AUTOSAR XML (schema 00048)
package /SecurityArchitecture/ComponentTypes
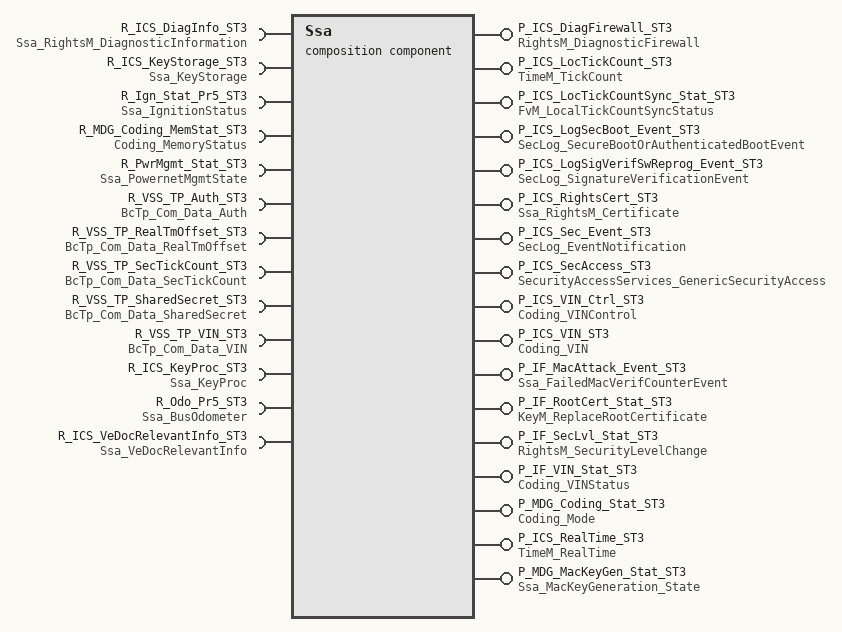
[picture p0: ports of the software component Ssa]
  composition sw component type Ssa: data-type-mapping=SSATypeMappingSet
    15 x provide port:
      P_ICS_DiagFirewall_ST3: provided-interface=RightsM_DiagnosticFirewall
        provided-com-specs:
          operation=GetDiagnosticUserRole, queue-length=1
          operation=IsEnhancedAccessRightGranted, queue-length=1
      P_ICS_LocTickCount_ST3: server-com-spec{operation=Get, queue-length=1}, provided-interface=TimeM_TickCount
      P_ICS_LocTickCountSync_Stat_ST3: server-com-spec{operation=Get, queue-length=1}, provided-interface=FvM_LocalTickCountSyncStatus
      P_ICS_LogSecBoot_Event_ST3: server-com-spec{operation=SecureBootOrAuthenticatedBoot, queue-length=1}, provided-interface=SecLog_SecureBootOrAuthenticatedBootEvent
      P_ICS_LogSigVerifSwReprog_Event_ST3: server-com-spec{operation=SignatureVerification, queue-length=1}, provided-interface=SecLog_SignatureVerificationEvent
      P_ICS_RightsCert_ST3: server-com-spec{operation=GetDiagAuthCertSerialNumber_SecurityAccess, queue-length=1}, provided-interface=Ssa_RightsM_Certificate
      P_ICS_Sec_Event_ST3: nonqueued-sender-com-spec{data-element=Data, init-value=constant-reference=Ssa_Init_Zero_7Byte}, provided-interface=SecLog_EventNotification
      P_ICS_SecAccess_ST3: provided-com-specs=[{operation=CompareKey, queue-length=1}, {operation=GetSeed, queue-length=1}], provided-interface=SecurityAccessServices_GenericSecurityAccess
      P_ICS_VIN_Ctrl_ST3: provided-interface=Coding_VINControl
        provided-com-specs:
          operation=GetStoreState, queue-length=1
          operation=Lock, queue-length=1
          operation=Set, queue-length=1
      P_ICS_VIN_ST3: server-com-spec{operation=Get, queue-length=1}, provided-interface=Coding_VIN
      P_IF_MacAttack_Event_ST3: queued-sender-com-spec=data-element=Event, provided-interface=Ssa_FailedMacVerifCounterEvent
      P_IF_RootCert_Stat_ST3: nonqueued-sender-com-spec{data-element=isProductive, init-value=constant-reference=Ssa_Init_boolean_False}, provided-interface=KeyM_ReplaceRootCertificate  # Notifies application about the change of the root certificate to a productive one.
      P_IF_SecLvl_Stat_ST3: nonqueued-sender-com-spec{data-element=currentLevel, init-value=constant-reference=Ssa_Init_Zero_uint8}, provided-interface=RightsM_SecurityLevelChange
      P_IF_VIN_Stat_ST3: nonqueued-sender-com-spec{data-element=status, init-value=constant-reference=Ssa_Init_VINStatus_VIN_STATUS_VIN_CORRECT_RECEIVED}, provided-interface=Coding_VINStatus  # Notifies application about the VIN status.
      P_MDG_Coding_Stat_ST3: mode-switch-sender-com-spec{enhanced-mode-api=false, mode-group=CodingStatus, queue-length=1}, provided-interface=Coding_Mode  # Notifies application about an ongoing, successful or failed coding attempt.
    10 x require port:
      R_ICS_DiagInfo_ST3: client-com-spec=Get, required-interface=Ssa_RightsM_DiagnosticInformation
      R_ICS_KeyStorage_ST3: client-com-spec=StorePermanently, required-interface=Ssa_KeyStorage  # Requests for storing the key material or certificates permanently i.e. for making them persistent.
      R_Ign_Stat_Pr5_ST3: nonqueued-receiver-com-spec{data-element=Ign_Stat_Pr5_ST3, end-to-end-transformation-com-spec-props=disable-end-to-end-check=true, filter=data-filter-type=ALWAYS, init-value=constant-reference=Ssa_Init_IgnitionStatus}, required-interface=Ssa_IgnitionStatus
      R_MDG_Coding_MemStat_ST3: mode-switch-receiver-com-spec{enhanced-mode-api=false, mode-group=MemoryStatus, supports-asynchronous-mode-switch=false}, required-interface=Coding_MemoryStatus
      R_PwrMgmt_Stat_ST3: nonqueued-receiver-com-spec{data-element=PN14_DDP_Sw_Stat_ST3, filter=data-filter-type=ALWAYS, init-value=constant-reference=Ssa_Init_PowernetMgmtState}, required-interface=Ssa_PowernetMgmtState
      R_VSS_TP_Auth_ST3: nonqueued-receiver-com-spec{data-element=VSS_TP_Auth_ST3, filter=data-filter-type=ALWAYS, init-value=constant-reference=Ssa_Init_ComSignal_8Byte}, required-interface=BcTp_Com_Data_Auth  # Configuration Variant(s): Not in VSM.
      R_VSS_TP_RealTmOffset_ST3: nonqueued-receiver-com-spec{data-element=VSS_TP_RealTmOffset_ST3, filter=data-filter-type=ALWAYS, init-value=constant-reference=Ssa_Init_ComSignal_8Byte}, required-interface=BcTp_Com_Data_RealTmOffset  # Configuration Variant(s): Not in VSM.
      R_VSS_TP_SecTickCount_ST3: nonqueued-receiver-com-spec{data-element=VSS_TP_SecTickCount_ST3, alive-timeout=1, filter=data-filter-type=ALWAYS, init-value=constant-reference=Ssa_Init_ComSignal_8Byte}, required-interface=BcTp_Com_Data_SecTickCount  # Configuration Variant(s): Not in VSM.
      R_VSS_TP_SharedSecret_ST3: nonqueued-receiver-com-spec{data-element=VSS_TP_SharedSecret_ST3, filter=data-filter-type=ALWAYS, init-value=constant-reference=Ssa_Init_ComSignal_8Byte}, required-interface=BcTp_Com_Data_SharedSecret  # Configuration Variant(s): Not in VSM.
      R_VSS_TP_VIN_ST3: nonqueued-receiver-com-spec{data-element=VSS_TP_VIN_ST3, alive-timeout=5, filter=data-filter-type=ALWAYS, init-value=constant-reference=Ssa_Init_ComSignal_8Byte}, required-interface=BcTp_Com_Data_VIN  # Configuration Variant(s): Not in VSM.
    provide port P_ICS_RealTime_ST3: provided-com-specs=[{operation=Compare, queue-length=1}, {operation=Get, queue-length=1}, {operation=Set, queue-length=1}], provided-interface=TimeM_RealTime
    require port R_ICS_KeyProc_ST3: required-com-specs=[GenerateKeyPair, PrepareKeyExchange], required-interface=Ssa_KeyProc  # Requests for preparing the key exchange operation, e.g. for generating the private key.
    require port R_Odo_Pr5_ST3: nonqueued-receiver-com-spec{data-element=DI_Odo_Pr5_ST3, end-to-end-transformation-com-spec-props=disable-end-to-end-check=true, filter=data-filter-type=ALWAYS, init-value=constant-reference=Ssa_Init_BusOdometerRecord}, required-interface=Ssa_BusOdometer
    provide port P_MDG_MacKeyGen_Stat_ST3: mode-switch-sender-com-spec{enhanced-mode-api=false, mode-group=State, queue-length=1}, provided-interface=Ssa_MacKeyGeneration_State  # Notifies application about an ongoing MAC key generation.
    require port R_ICS_VeDocRelevantInfo_ST3: client-com-spec=GetData, required-interface=Ssa_VeDocRelevantInfo  # Requests for the VeDoc relevant information, e.g., to be used as common name in the Trust Model CSR.
    10 x component:
      Ssa_BcTp: type=Ssa_BcTp
      Ssa_Cdd: type=Ssa_Cdd
      Ssa_CertP: type=Ssa_CertP
      Ssa_Coding: type=Ssa_Coding
      Ssa_FvM: type=Ssa_FvM
      Ssa_KeyM: type=Ssa_KeyM
      Ssa_ProcCtrl: type=Ssa_ProcCtrl
      Ssa_RightsM: type=Ssa_RightsM
      Ssa_SecLog: type=Ssa_SecLog
      Ssa_TimeM: type=Ssa_TimeM
    connect Ssa_BcTp.Coding_ReceiveVIN -> Ssa_Coding.Coding_Com_ReceiveVIN
    connect Ssa_BcTp.FvM_ReceiveTickCount -> Ssa_FvM.FvM_Com_ReceiveTickCount
    connect Ssa_BcTp.FvM_ReceiveTickCountTimeout -> Ssa_FvM.FvM_Com_ReceiveTickCountTimeout
    connect Ssa_BcTp.KeyM_ReceiveSharedSecret -> Ssa_KeyM.KeyM_Com_ReceiveSharedSecret
    connect Ssa_BcTp.RightsM_ReceiveAuthenticationBroadcast -> Ssa_RightsM.RightsM_ReceiveAuthenticationBroadcast
    connect Ssa_BcTp.SecLog_MacVerificationSecureBroadcastEvent -> Ssa_SecLog.BcTp_SecureBroadcastVerificationStatus
    connect Ssa_BcTp.TimeM_ReceiveRealTimeOffset -> Ssa_TimeM.TimeM_Com_ReceiveRealTimeOffset
    connect Ssa_Cdd.SsaCdd_CryptoInterface -> Ssa_Coding.SsaCdd_Csm
    connect Ssa_CertP.CertP_Functions -> Ssa_Coding.CertP_Functions
    connect Ssa_Coding.Coding_VIN -> Ssa_CertP.Coding_VIN
    connect Ssa_Coding.RoutineServices_Routine_Evaluate_Data_Verification_Certificate -> Ssa_ProcCtrl.RC_Evaluate_Data_Verification_Certificate
    connect Ssa_Coding.RoutineServices_Routine_Reset_VIN_Values -> Ssa_ProcCtrl.RC_Reset_VIN_Values
    connect Ssa_Coding.RoutineServices_Routine_Verify_Signature -> Ssa_ProcCtrl.RC_Verify_Signature
    connect Ssa_FvM.FvM_FreshnessManagement -> Ssa_BcTp.FvM_FreshnessManagement
    connect Ssa_FvM.FvM_SendLocalTickCountAndSyncStatus -> Ssa_SecLog.ReceiveLocalTickCountAndSyncStatus
    connect Ssa_FvM.FvM_InitialTickCount -> Ssa_TimeM.FvM_InitialTickCount
    connect Ssa_FvM.SendChangeTickCountEvent -> Ssa_TimeM.ReceiveChangeTickCountEvent
    connect Ssa_KeyM.KeyM_Certificate -> Ssa_Coding.KeyM_Certificate
    connect Ssa_KeyM.DataServices_DID_018F_Secured_PDU_Data_IDs_and_Key_CMACs -> Ssa_ProcCtrl.DS_DID_018F_Secured_PDU_Data_IDs_and_Key_CMACs
    connect Ssa_KeyM.DataServices_DID_0191_Generated_Random_Number -> Ssa_ProcCtrl.DS_DID_0191_Generated_Random_Number
    connect Ssa_KeyM.DataServices_DID_0191_Generated_Random_Number_Result -> Ssa_ProcCtrl.DS_DID_0191_Generated_Random_Number_Result
    connect Ssa_KeyM.DataServices_DID_0199_Certificates -> Ssa_ProcCtrl.DS_DID_0199_Certificates
    connect Ssa_KeyM.DataServices_DID_0199_Data_Signature -> Ssa_ProcCtrl.DS_DID_0199_Data_Signature
    connect Ssa_KeyM.DataServices_DID_0199_Ephemeral_ECU_Public_Key -> Ssa_ProcCtrl.DS_DID_0199_Ephemeral_ECU_Public_Key
    connect Ssa_KeyM.DataServices_DID_0199_Nonce -> Ssa_ProcCtrl.DS_DID_0199_Nonce
    connect Ssa_KeyM.DataServices_DID_019A_Trust_model_ECU_CSR -> Ssa_ProcCtrl.DS_DID_019A_Trust_model_ECU_CSR
    connect Ssa_KeyM.DataServices_DID_019B_Trust_model_ECU_Certificate -> Ssa_ProcCtrl.DS_DID_019B_Trust_model_ECU_Certificate
    connect Ssa_KeyM.DataServices_DID_019C_Trust_model_Intermediate_CA_Certificate -> Ssa_ProcCtrl.DS_DID_019C_Trust_model_Intermediate_CA_Certificate
    connect Ssa_KeyM.DataServices_DID_019D_Trust_model_Backend_CA_certificate -> Ssa_ProcCtrl.DS_DID_019D_Trust_model_Backend_CA_certificate
    connect Ssa_KeyM.DataServices_DID_019E_Trust_model_Root_CA_certificate -> Ssa_ProcCtrl.DS_DID_019E_Trust_model_Root_CA_certificate
    connect Ssa_KeyM.DataServices_DID_019F_Trust_model_certificates -> Ssa_ProcCtrl.DS_DID_019F_Trust_model_certificates
    connect Ssa_KeyM.RoutineServices_Routine_Certificate_Self_Check -> Ssa_ProcCtrl.RC_Certificate_Self_Check
    connect Ssa_KeyM.RoutineServices_Routine_Replace_Certificates -> Ssa_ProcCtrl.RC_Replace_Certificates
    connect Ssa_KeyM.RoutineServices_Replace_Trust_model_Certificates -> Ssa_ProcCtrl.RC_Replace_Trust_model_Certificates
    connect Ssa_KeyM.RoutineServices_Replace_Trust_model_Root_Certificate -> Ssa_ProcCtrl.RC_Replace_Trust_model_Root_Certificate
    connect Ssa_KeyM.RoutineServices_Trust_Model_SecOC_ECU_Shared_Secret_Distribution -> Ssa_ProcCtrl.RC_Trust_Model_SecOC_ECU_Shared_Secret_Distribution
    connect Ssa_ProcCtrl.ProcCtrl_DispatchServices_Sender -> Ssa_ProcCtrl.ProcCtrl_DispatchServices_Receiver
    connect Ssa_RightsM.RightsM_DiagnosticChannel -> Ssa_KeyM.RightsM_DiagnosticChannel
    connect Ssa_RightsM.RightsM_EnhancedRights -> Ssa_KeyM.RightsM_EnhancedRights
    connect Ssa_RightsM.RightsM_Nonce -> Ssa_KeyM.RightsM_Nonce
    connect Ssa_RightsM.RoutineServices_Routine_Authenticate_Diagnostic_User_or_Tester -> Ssa_ProcCtrl.RC_Authenticate_Diagnostic_User_or_Tester
    connect Ssa_RightsM.RoutineServices_Routine_Enhance_Access_Rights -> Ssa_ProcCtrl.RC_Enhance_Access_Rights
    connect Ssa_RightsM.RoutineServices_Routine_Synchronize_Secured_System_Date_and_Time -> Ssa_ProcCtrl.RC_Synchronize_Secured_System_Date_and_Time
    connect Ssa_RightsM.RightsM_SecurityAccess -> Ssa_ProcCtrl.SecurityAccess_Client
    connect Ssa_SecLog.SecLog_FailedCertVerificationEvent -> Ssa_CertP.SecLog_FailedCertVerificationEvent
    connect Ssa_SecLog.SecLog_SuccessfulCertVerificationEvent -> Ssa_CertP.SecLog_SuccessfulCertVerificationEvent
    connect Ssa_SecLog.SecLog_ChangeVinEvent -> Ssa_Coding.SecLog_ChangeVinEvent
    connect Ssa_SecLog.SecLog_SignatureVerificationEvent_VerifySignatureVariantCoding -> Ssa_Coding.SecLog_SignatureVerificationEvent_VerifySignatureVariantCoding
    connect Ssa_SecLog.SecLog_SuccessfulDiagServiceExecutionEvent_EcuSharedSecretDistribution -> Ssa_KeyM.SecLog_SuccessfulDiagServiceExecutionEvent_EcuSharedSecretDistribution
    connect Ssa_SecLog.SecLog_SuccessfulDiagServiceExecutionEvent_ReplaceCert -> Ssa_KeyM.SecLog_SuccessfulDiagServiceExecutionEvent_ReplaceCert
    connect Ssa_SecLog.DataServices_Security_Event_Log_Current_Counter_Values_Read_Security_Event_Log_Current_Counter_Values -> Ssa_ProcCtrl.DS_Security_Event_Log_Current_Counter_Values_Read_Security_Event_Log_Current_Counter_Values
    connect Ssa_SecLog.DataServices_Security_Event_Log_Read_Security_Event_Log_Entry -> Ssa_ProcCtrl.DS_Security_Event_Log_Read_Security_Event_Log_Entry
    connect Ssa_SecLog.SecLog_AuthorizationBySecurityAccess -> Ssa_RightsM.SecLog_AuthorizationBySecurityAccess
    connect Ssa_SecLog.SecLog_EcuIndividualAclReplacementEvent -> Ssa_RightsM.SecLog_EcuIndividualAclReplacementEvent
    connect Ssa_SecLog.SecLog_RightsManagementEvent -> Ssa_RightsM.SecLog_RightsManagementEvent
    connect Ssa_SecLog.SecLog_SuccessfulAuthAndEnhanceRights -> Ssa_RightsM.SecLog_SuccessfulAuthAndEnhanceRights
    connect Ssa_SecLog.SecLog_SuccessfulDiagServiceExecutionEvent_ActivateDebugIf -> Ssa_RightsM.SecLog_SuccessfulDiagServiceExecutionEvent_ActivateDebugIf
    connect Ssa_SecLog.SecLog_SuccessfulDiagServiceExecutionEvent_ClearSarMemory -> Ssa_RightsM.SecLog_SuccessfulDiagServiceExecutionEvent_ClearSarMemory
    connect Ssa_SecLog.SecLog_SuccessfulDiagServiceExecutionEvent_EnableSarMemOverwrite -> Ssa_RightsM.SecLog_SuccessfulDiagServiceExecutionEvent_EnableSarMemOverwrite
    connect Ssa_SecLog.SecLog_SuccessfulDiagServiceExecutionEvent_EraseMemory -> Ssa_RightsM.SecLog_SuccessfulDiagServiceExecutionEvent_EraseMemory
    connect Ssa_SecLog.SecLog_ChangeTickCountOrDateAndTimeEvent -> Ssa_TimeM.SecLog_ChangeTickCountOrDateAndTimeEvent
    connect Ssa_TimeM.TimeM_RealTime -> Ssa_CertP.TimeM_RealTime
    connect Ssa_TimeM.TimeM_TickCount -> Ssa_KeyM.TimeM_TickCount
    connect Ssa_TimeM.TimeM_TimeRawData -> Ssa_KeyM.TimeM_TimeRawData
    delegate Ssa_RightsM.RightsM_DiagnosticFirewall <-> outer port P_ICS_DiagFirewall_ST3
    delegate Ssa_FvM.FvM_LocalTickCountSyncStatus <-> outer port P_ICS_LocTickCountSync_Stat_ST3
    delegate Ssa_SecLog.SecLog_SecureBootOrAuthenticatedBootEvent <-> outer port P_ICS_LogSecBoot_Event_ST3
    delegate Ssa_SecLog.SecLog_SignatureVerificationEvent_VerifySignatureSwReprogramming <-> outer port P_ICS_LogSigVerifSwReprog_Event_ST3
    delegate Ssa_RightsM.RightsM_Certificate <-> outer port P_ICS_RightsCert_ST3
    delegate Ssa_SecLog.SecLog_EventNotification <-> outer port P_ICS_Sec_Event_ST3
    delegate Ssa_ProcCtrl.SecurityAccess_Server <-> outer port P_ICS_SecAccess_ST3
    delegate Ssa_Coding.Coding_VINControl <-> outer port P_ICS_VIN_Ctrl_ST3
    delegate Ssa_SecLog.Ssa_FailedMacVerifCounterEvent <-> outer port P_IF_MacAttack_Event_ST3
    delegate Ssa_KeyM.KeyM_ReplaceRootCertificate <-> outer port P_IF_RootCert_Stat_ST3
    delegate Ssa_RightsM.RightsM_SecurityLevelChange <-> outer port P_IF_SecLvl_Stat_ST3
    delegate Ssa_Coding.Coding_VINStatus <-> outer port P_IF_VIN_Stat_ST3
    delegate Ssa_Coding.Coding_Mode <-> outer port P_MDG_Coding_Stat_ST3
    delegate Ssa_RightsM.Ssa_RightsM_DiagnosticInformation <-> outer port R_ICS_DiagInfo_ST3
    delegate Ssa_KeyM.Ssa_KeyStorage <-> outer port R_ICS_KeyStorage_ST3
    delegate Ssa_SecLog.Ssa_IgnitionStatus <-> outer port R_Ign_Stat_Pr5_ST3
    delegate Ssa_Coding.Coding_MemoryStatus <-> outer port R_MDG_Coding_MemStat_ST3
    delegate Ssa_TimeM.Ssa_PowernetMgmtState <-> outer port R_PwrMgmt_Stat_ST3
    delegate Ssa_BcTp.ReceiveDiagnosticAuthentication <-> outer port R_VSS_TP_Auth_ST3
    delegate Ssa_BcTp.ReceiveRealTimeOffset <-> outer port R_VSS_TP_RealTmOffset_ST3
    delegate Ssa_BcTp.ReceiveTickCount <-> outer port R_VSS_TP_SecTickCount_ST3
    delegate Ssa_BcTp.ReceiveSharedSecret <-> outer port R_VSS_TP_SharedSecret_ST3
    delegate Ssa_BcTp.ReceiveVIN <-> outer port R_VSS_TP_VIN_ST3
    connect Ssa_SecLog.SecLog_SuccessfulDiagServiceExecutionEvent_ReplaceTrustModelCert -> Ssa_KeyM.SecLog_SuccessfulDiagServiceExecutionEvent_ReplaceTrustModelCert
    connect Ssa_SecLog.SecLog_SuccessfulDiagServiceExecutionEvent_ReplaceTrustModeRootCert -> Ssa_KeyM.SecLog_SuccessfulDiagServiceExecutionEvent_ReplaceTrustModeRootCert
    connect Ssa_BcTp.Coding_ReceiveVINTimeout -> Ssa_Coding.Coding_ReceiveVINTimeout
    connect Ssa_Cdd.SsaCdd_CertInterface -> Ssa_KeyM.SsaCdd_TrustModel
    connect Ssa_KeyM.RoutineServices_Inject_Seed -> Ssa_ProcCtrl.RC_Inject_Seed
    connect Ssa_KeyM.RoutineServices_Trust_Model_Generate_Key_Pair -> Ssa_ProcCtrl.RC_Trust_Model_Generate_Key_Pair
    connect Ssa_ProcCtrl.DiagnosticService_Authentication_0x29 -> Ssa_Cdd.DiagnosticService_Authentication_0x29
    delegate Ssa_KeyM.Ssa_KeyProc <-> outer port R_ICS_KeyProc_ST3
    delegate Ssa_RightsM.Ssa_BusOdometer <-> outer port R_Odo_Pr5_ST3
    connect Ssa_Cdd.SsaCdd_CryptoInterface -> Ssa_RightsM.SsaCdd_Csm
    connect Ssa_CertP.CertP_Functions -> Ssa_KeyM.CertP_Functions
    connect Ssa_CertP.CertP_Functions -> Ssa_RightsM.CertP_Functions
    connect Ssa_Coding.Coding_VIN -> Ssa_KeyM.Coding_VIN
    connect Ssa_FvM.FvM_SendLocalTickCountAndSyncStatus -> Ssa_TimeM.ReceiveLocalTickCountAndSyncStatus
    connect Ssa_KeyM.KeyM_Certificate -> Ssa_RightsM.KeyM_Certificate
    connect Ssa_KeyM.KeyM_Certificate -> Ssa_SecLog.KeyM_Certificate
    connect Ssa_RightsM.RightsM_DiagnosticChannel -> Ssa_SecLog.RightsM_DiagnosticChannel
    connect Ssa_TimeM.TimeM_RealTime -> Ssa_KeyM.TimeM_RealTime
    connect Ssa_TimeM.TimeM_RealTime -> Ssa_RightsM.TimeM_RealTime
    connect Ssa_TimeM.TimeM_TickCount -> Ssa_RightsM.TimeM_TickCount
    connect Ssa_TimeM.TimeM_RealTime -> Ssa_SecLog.TimeM_RealTime
    connect Ssa_TimeM.TimeM_TickCount -> Ssa_SecLog.TimeM_TickCount
    delegate Ssa_TimeM.TimeM_TickCount <-> outer port P_ICS_LocTickCount_ST3
    delegate Ssa_Coding.Coding_VIN <-> outer port P_ICS_VIN_ST3
    connect Ssa_RightsM.RoutineServices_Routine_Enhance_Access_Rights -> Ssa_KeyM.RC_Enhance_Access_Rights
    delegate Ssa_TimeM.TimeM_RealTime <-> outer port P_ICS_RealTime_ST3
    connect Ssa_Cdd.SsaCdd_CryptoInterface -> Ssa_CertP.SsaCdd_Csm
    connect Ssa_Cdd.SsaCdd_CryptoInterface -> Ssa_KeyM.SsaCdd_Csm
    connect Ssa_SecLog.SecLog_FailedCertVerificationEvent -> Ssa_KeyM.SecLog_FailedCertVerificationEvent
    connect Ssa_SecLog.SecLog_SuccessfulCertVerificationEvent -> Ssa_KeyM.SecLog_SuccessfulCertVerificationEvent
    connect Ssa_SecLog.SecLog_SuccessfulDiagServiceExecutionEvent_InjectSeed -> Ssa_KeyM.SecLog_SuccessfulDiagServiceExecutionEvent_InjectSeed
    connect Ssa_SecLog.SecLog_SuccessfulDiagServiceExecutionEvent_TrustModelGenerateKeyPair -> Ssa_KeyM.SecLog_SuccessfulDiagServiceExecutionEvent_TrustModelGenerateKeyPair
    delegate Ssa_KeyM.Ssa_MacKeyGeneration_State <-> outer port P_MDG_MacKeyGen_Stat_ST3
    delegate Ssa_KeyM.Ssa_VeDocRelevantInfo <-> outer port R_ICS_VeDocRelevantInfo_ST3
    connect Ssa_Cdd.SsaCdd_KeyInterface -> Ssa_KeyM.SsaCdd_Keys
    connect Ssa_SecLog.SecLog_SuccessfulDiagServiceExecutionEvent_TrustModeEcuSharedSecretDistribution -> Ssa_KeyM.SecLog_SuccessfulDiagServiceExecutionEvent_TrustModelEcuSharedSecretDistribution
